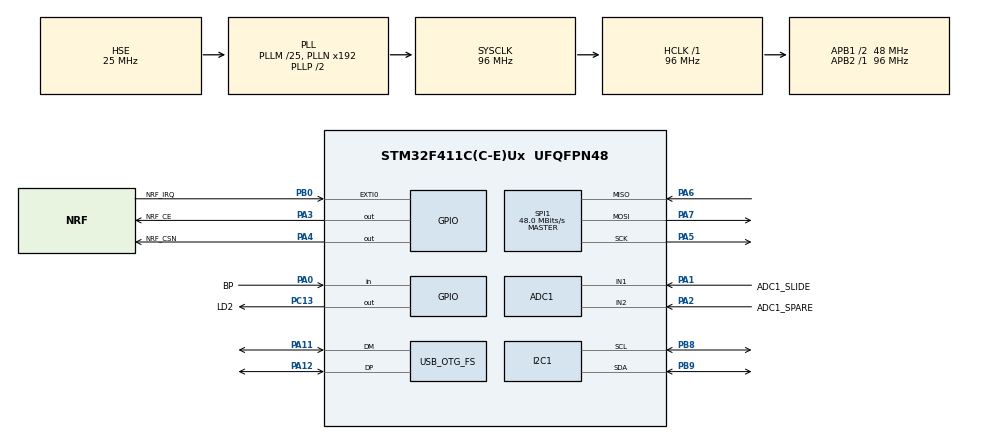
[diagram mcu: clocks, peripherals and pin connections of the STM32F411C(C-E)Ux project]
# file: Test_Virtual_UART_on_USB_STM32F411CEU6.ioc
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ADC1.Channel-0\#ChannelRegularConversion=ADC_CHANNEL_1
ADC1.NbrOfConversionFlag=1
ADC1.Rank-0\#ChannelRegularConversion=1
ADC1.SamplingTime-0\#ChannelRegularConversion=ADC_SAMPLETIME_3CYCLES
ADC1.master=1
Mcu.Family=STM32F4
Mcu.Name=STM32F411C(C-E)Ux
Mcu.Package=UFQFPN48
NVIC.OTG_FS_IRQn=true\:0\:0\:false\:false\:true\:false\:true\:true
NVIC.PriorityGroup=NVIC_PRIORITYGROUP_4
PA0-WKUP.GPIO_Label=BP
PA0-WKUP.Signal=GPIO_Input
PA1.GPIO_Label=ADC1_SLIDE
PA1.Signal=ADCx_IN1
PA11.Mode=Device_Only
PA11.Signal=USB_OTG_FS_DM
PA12.Mode=Device_Only
PA12.Signal=USB_OTG_FS_DP
PA13.Mode=Serial_Wire
PA13.Signal=SYS_JTMS-SWDIO
PA14.Mode=Serial_Wire
PA14.Signal=SYS_JTCK-SWCLK
PA2.GPIO_Label=ADC1_SPARE
PA2.Signal=ADCx_IN2
PA3.GPIO_Label=NRF_CE
PA3.Signal=GPIO_Output
PA4.GPIO_Label=NRF_CSN
PA4.Signal=GPIO_Output
PA5.Mode=Full_Duplex_Master
PA5.Signal=SPI1_SCK
PA6.Mode=Full_Duplex_Master
PA6.Signal=SPI1_MISO
PA7.Mode=Full_Duplex_Master
PA7.Signal=SPI1_MOSI
PB0.GPIO_Label=NRF_IRQ
PB0.Signal=GPXTI0
PB8.Mode=I2C
PB8.Signal=I2C1_SCL
PB9.Mode=I2C
PB9.Signal=I2C1_SDA
PC13-ANTI_TAMP.GPIO_Label=LD2
PC13-ANTI_TAMP.Signal=GPIO_Output
PC14-OSC32_IN.Mode=LSE-External-Oscillator
PC14-OSC32_IN.Signal=RCC_OSC32_IN
PC15-OSC32_OUT.Mode=LSE-External-Oscillator
PC15-OSC32_OUT.Signal=RCC_OSC32_OUT
PH0\ -\ OSC_IN.Mode=HSE-External-Oscillator
PH0\ -\ OSC_IN.Signal=RCC_OSC_IN
PH1\ -\ OSC_OUT.Mode=HSE-External-Oscillator
PH1\ -\ OSC_OUT.Signal=RCC_OSC_OUT
ProjectManager.HeapSize=0x200
ProjectManager.StackSize=0x400
ProjectManager.TargetToolchain=STM32CubeIDE
RCC.48MHZClocksFreq_Value=48000000
RCC.AHBFreq_Value=96000000
RCC.APB1CLKDivider=RCC_HCLK_DIV2
RCC.APB1Freq_Value=48000000
RCC.APB1TimFreq_Value=96000000
RCC.APB2Freq_Value=96000000
RCC.APB2TimFreq_Value=96000000
RCC.CortexFreq_Value=96000000
RCC.HCLKFreq_Value=96000000
RCC.HSE_VALUE=25000000
RCC.HSI_VALUE=16000000
RCC.PLLM=25
RCC.SYSCLKFreq_VALUE=96000000
RCC.SYSCLKSource=RCC_SYSCLKSOURCE_PLLCLK
RCC.VCOOutputFreq_Value=192000000
SH.ADCx_IN1.0=ADC1_IN1,IN1
SH.ADCx_IN2.0=ADC1_IN2,IN2
SPI1.CalculateBaudRate=48.0 MBits/s
SPI1.Direction=SPI_DIRECTION_2LINES
SPI1.Mode=SPI_MODE_MASTER
SPI1.VirtualType=VM_MASTER
USB_DEVICE.CLASS_NAME_FS=CDC
USB_DEVICE.VirtualMode=Cdc
USB_DEVICE.VirtualModeFS=Cdc_FS
USB_OTG_FS.VirtualMode=Device_Only
VP_USB_DEVICE_VS_USB_DEVICE_CDC_FS.Mode=CDC_FS
board=custom

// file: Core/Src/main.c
/* USER CODE BEGIN Header */
/**
  ******************************************************************************
  * @file           : main.c
  * @brief          : Main program body
  ******************************************************************************
  * @attention
  *
  * Copyright (c) 2025 STMicroelectronics.
  * All rights reserved.
  *
  * This software is licensed under terms that can be found in the LICENSE file
  * in the root directory of this software component.
  * If no LICENSE file comes with this software, it is provided AS-IS.
  *
  ******************************************************************************
  */
/* USER CODE END Header */
#include "main.h"
#include "usb_device.h"

ADC_HandleTypeDef hadc1;

I2C_HandleTypeDef hi2c1;

SPI_HandleTypeDef hspi1;

void SystemClock_Config(void);
static void MX_GPIO_Init(void);
static void MX_SPI1_Init(void);
static void MX_I2C1_Init(void);
static void MX_ADC1_Init(void);

int main(void)
{

  /* MCU Configuration--------------------------------------------------------*/

  /* Reset of all peripherals, Initializes the Flash interface and the Systick. */
  HAL_Init();

  /* Configure the system clock */
  SystemClock_Config();

  /* Initialize all configured peripherals */
  MX_GPIO_Init();
  MX_SPI1_Init();
  MX_I2C1_Init();
  MX_ADC1_Init();
  MX_USB_DEVICE_Init();

  /* Infinite loop */
  /* USER CODE BEGIN WHILE */
  while (1)
  {
	  // creating a modification in the project
	  // doing an other modif to push it in GIT HUB
    /* USER CODE END WHILE */

  }
}

void SystemClock_Config(void)
{
  RCC_OscInitTypeDef RCC_OscInitStruct = {0};
  RCC_ClkInitTypeDef RCC_ClkInitStruct = {0};

  /** Configure the main internal regulator output voltage
  */
  __HAL_RCC_PWR_CLK_ENABLE();
  __HAL_PWR_VOLTAGESCALING_CONFIG(PWR_REGULATOR_VOLTAGE_SCALE1);

  /** Initializes the RCC Oscillators according to the specified parameters
  * in the RCC_OscInitTypeDef structure.
  */
  RCC_OscInitStruct.OscillatorType = RCC_OSCILLATORTYPE_HSE;
  RCC_OscInitStruct.HSEState = RCC_HSE_ON;
  RCC_OscInitStruct.PLL.PLLState = RCC_PLL_ON;
  RCC_OscInitStruct.PLL.PLLSource = RCC_PLLSOURCE_HSE;
  RCC_OscInitStruct.PLL.PLLM = 25;
  RCC_OscInitStruct.PLL.PLLN = 192;
  RCC_OscInitStruct.PLL.PLLP = RCC_PLLP_DIV2;
  RCC_OscInitStruct.PLL.PLLQ = 4;
  if (HAL_RCC_OscConfig(&RCC_OscInitStruct) != HAL_OK)
  {
    Error_Handler();
  }

  /** Initializes the CPU, AHB and APB buses clocks
  */
  RCC_ClkInitStruct.ClockType = RCC_CLOCKTYPE_HCLK|RCC_CLOCKTYPE_SYSCLK
                              |RCC_CLOCKTYPE_PCLK1|RCC_CLOCKTYPE_PCLK2;
  RCC_ClkInitStruct.SYSCLKSource = RCC_SYSCLKSOURCE_PLLCLK;
  RCC_ClkInitStruct.AHBCLKDivider = RCC_SYSCLK_DIV1;
  RCC_ClkInitStruct.APB1CLKDivider = RCC_HCLK_DIV2;
  RCC_ClkInitStruct.APB2CLKDivider = RCC_HCLK_DIV1;

  if (HAL_RCC_ClockConfig(&RCC_ClkInitStruct, FLASH_LATENCY_3) != HAL_OK)
  {
    Error_Handler();
  }
}

static void MX_ADC1_Init(void)
{

  ADC_ChannelConfTypeDef sConfig = {0};

  /** Configure the global features of the ADC (Clock, Resolution, Data Alignment and number of conversion)
  */
  hadc1.Instance = ADC1;
  hadc1.Init.ClockPrescaler = ADC_CLOCK_SYNC_PCLK_DIV4;
  hadc1.Init.Resolution = ADC_RESOLUTION_12B;
  hadc1.Init.ScanConvMode = DISABLE;
  hadc1.Init.ContinuousConvMode = DISABLE;
  hadc1.Init.DiscontinuousConvMode = DISABLE;
  hadc1.Init.ExternalTrigConvEdge = ADC_EXTERNALTRIGCONVEDGE_NONE;
  hadc1.Init.ExternalTrigConv = ADC_SOFTWARE_START;
  hadc1.Init.DataAlign = ADC_DATAALIGN_RIGHT;
  hadc1.Init.NbrOfConversion = 1;
  hadc1.Init.DMAContinuousRequests = DISABLE;
  hadc1.Init.EOCSelection = ADC_EOC_SINGLE_CONV;
  if (HAL_ADC_Init(&hadc1) != HAL_OK)
  {
    Error_Handler();
  }

  /** Configure for the selected ADC regular channel its corresponding rank in the sequencer and its sample time.
  */
  sConfig.Channel = ADC_CHANNEL_1;
  sConfig.Rank = 1;
  sConfig.SamplingTime = ADC_SAMPLETIME_3CYCLES;
  if (HAL_ADC_ConfigChannel(&hadc1, &sConfig) != HAL_OK)
  {
    Error_Handler();
  }

}

static void MX_I2C1_Init(void)
{

  hi2c1.Instance = I2C1;
  hi2c1.Init.ClockSpeed = 100000;
  hi2c1.Init.DutyCycle = I2C_DUTYCYCLE_2;
  hi2c1.Init.OwnAddress1 = 0;
  hi2c1.Init.AddressingMode = I2C_ADDRESSINGMODE_7BIT;
  hi2c1.Init.DualAddressMode = I2C_DUALADDRESS_DISABLE;
  hi2c1.Init.OwnAddress2 = 0;
  hi2c1.Init.GeneralCallMode = I2C_GENERALCALL_DISABLE;
  hi2c1.Init.NoStretchMode = I2C_NOSTRETCH_DISABLE;
  if (HAL_I2C_Init(&hi2c1) != HAL_OK)
  {
    Error_Handler();
  }

}

static void MX_SPI1_Init(void)
{

  /* SPI1 parameter configuration*/
  hspi1.Instance = SPI1;
  hspi1.Init.Mode = SPI_MODE_MASTER;
  hspi1.Init.Direction = SPI_DIRECTION_2LINES;
  hspi1.Init.DataSize = SPI_DATASIZE_8BIT;
  hspi1.Init.CLKPolarity = SPI_POLARITY_LOW;
  hspi1.Init.CLKPhase = SPI_PHASE_1EDGE;
  hspi1.Init.NSS = SPI_NSS_SOFT;
  hspi1.Init.BaudRatePrescaler = SPI_BAUDRATEPRESCALER_2;
  hspi1.Init.FirstBit = SPI_FIRSTBIT_MSB;
  hspi1.Init.TIMode = SPI_TIMODE_DISABLE;
  hspi1.Init.CRCCalculation = SPI_CRCCALCULATION_DISABLE;
  hspi1.Init.CRCPolynomial = 10;
  if (HAL_SPI_Init(&hspi1) != HAL_OK)
  {
    Error_Handler();
  }

}

static void MX_GPIO_Init(void)
{
  GPIO_InitTypeDef GPIO_InitStruct = {0};

  /* GPIO Ports Clock Enable */
  __HAL_RCC_GPIOC_CLK_ENABLE();
  __HAL_RCC_GPIOH_CLK_ENABLE();
  __HAL_RCC_GPIOA_CLK_ENABLE();
  __HAL_RCC_GPIOB_CLK_ENABLE();

  /*Configure GPIO pin Output Level */
  HAL_GPIO_WritePin(LD2_GPIO_Port, LD2_Pin, GPIO_PIN_RESET);

  /*Configure GPIO pin Output Level */
  HAL_GPIO_WritePin(GPIOA, NRF_CE_Pin|NRF_CSN_Pin, GPIO_PIN_RESET);

  /*Configure GPIO pin : LD2_Pin */
  GPIO_InitStruct.Pin = LD2_Pin;
  GPIO_InitStruct.Mode = GPIO_MODE_OUTPUT_PP;
  GPIO_InitStruct.Pull = GPIO_NOPULL;
  GPIO_InitStruct.Speed = GPIO_SPEED_FREQ_LOW;
  HAL_GPIO_Init(LD2_GPIO_Port, &GPIO_InitStruct);

  /*Configure GPIO pin : BP_Pin */
  GPIO_InitStruct.Pin = BP_Pin;
  GPIO_InitStruct.Mode = GPIO_MODE_INPUT;
  GPIO_InitStruct.Pull = GPIO_NOPULL;
  HAL_GPIO_Init(BP_GPIO_Port, &GPIO_InitStruct);

  /*Configure GPIO pins : NRF_CE_Pin NRF_CSN_Pin */
  GPIO_InitStruct.Pin = NRF_CE_Pin|NRF_CSN_Pin;
  GPIO_InitStruct.Mode = GPIO_MODE_OUTPUT_PP;
  GPIO_InitStruct.Pull = GPIO_NOPULL;
  GPIO_InitStruct.Speed = GPIO_SPEED_FREQ_LOW;
  HAL_GPIO_Init(GPIOA, &GPIO_InitStruct);

  /*Configure GPIO pin : NRF_IRQ_Pin */
  GPIO_InitStruct.Pin = NRF_IRQ_Pin;
  GPIO_InitStruct.Mode = GPIO_MODE_IT_RISING;
  GPIO_InitStruct.Pull = GPIO_NOPULL;
  HAL_GPIO_Init(NRF_IRQ_GPIO_Port, &GPIO_InitStruct);

}

void Error_Handler(void)
{
  __disable_irq();
  while (1)
  {
  }
}
